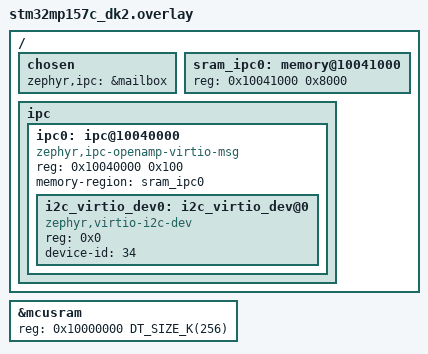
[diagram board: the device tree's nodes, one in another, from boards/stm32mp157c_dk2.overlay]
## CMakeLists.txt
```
cmake_minimum_required(VERSION 3.13.1)
# Copyright (c) 2024  STMicroelectronics
#
# SPDX-License-Identifier: Apache-2.0
#

include($ENV{ZEPHYR_BASE}/cmake/app/boilerplate.cmake NO_POLICY_SCOPE)

project(virtio_i2c_ram)

zephyr_compile_definitions(
  -DMETAL_MAX_DEVICE_REGIONS=2
  -DVIRTIO_SLAVE_ONLY
  )

target_include_directories(app PRIVATE $ENV{ZEPHYR_BASE}/drivers)
target_include_directories(app PRIVATE ${LIBMETAL_INCLUDE_DIR} ${OPENAMP_INCLUDE_DIR} ${PLATFORM_DIR})

target_sources(app PRIVATE src/main_remote.c)

target_include_directories(app PRIVATE ${CMAKE_CURRENT_SOURCE_DIR}/..)
```

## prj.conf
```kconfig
CONFIG_KERNEL_BIN_NAME="zephyr_virtio_i2c_eeprom"
CONFIG_PRINTK=n
CONFIG_IPM=y
CONFIG_PLATFORM_SPECIFIC_INIT=n
CONFIG_MAIN_STACK_SIZE=4096
CONFIG_HEAP_MEM_POOL_SIZE=16384
CONFIG_OPENAMP_MASTER=n
CONFIG_OPENAMP_RSC_TABLE=n
CONFIG_VIRTIO_MSG_SERVICE=y
CONFIG_VIRTIO_MSG_SERVICE_MODE_REMOTE=y
CONFIG_I2C=y
CONFIG_I2C_VIRTIO_DEV=y
CONFIG_I2C_TARGET_BUFFER_MODE=y
CONFIG_RAM_CONSOLE=y
CONFIG_RAM_CONSOLE_BUFFER_SIZE=1024
```

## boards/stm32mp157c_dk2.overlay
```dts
/*
 * Copyright (c) 2024, STMICROELECTRONICS
 *
 * SPDX-License-Identifier: Apache-2.0
 */

/ {
	chosen {
		/*
		 * shared memory reserved for the inter-processor communication
		 */
		zephyr,ipc = &mailbox;
	};


	sram_ipc0: memory@10041000 {
			#memory-region-cells = <0>;
			reg = <0x10041000 0x8000>;
		};

   	ipc {
		#address-cells = <1>;
		#size-cells = <1>;
		ipc0: ipc@10040000  {
			reg = <0x10040000  0x100>;
			compatible = "zephyr,ipc-openamp-virtio-msg";
			memory-region = <&sram_ipc0>;
			status = "okay";

			#address-cells = <1>;
			#size-cells = <0>;
			i2c_virtio_dev0: i2c_virtio_dev@0 {
				compatible = "zephyr,virtio-i2c-dev";
				reg = <0x0>;
                		device-id = <34>;
			};
		};
	};
};

&mcusram {
	reg = <0x10000000 DT_SIZE_K(256)>;
};
```

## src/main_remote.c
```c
// SPDX-License-Identifier: Apache-2.0

/* Copyright (c) 2024, STMicroelectronics */


#include <stdlib.h>
#include <stdio.h>
#include <string.h>

#include <zephyr/device.h>
#include <zephyr/drivers/sensor.h>
#include <zephyr/drivers/i2c.h>
#include <zephyr/drivers/i2c/target/eeprom.h>
#include <zephyr/drivers/ipm.h>
#include <zephyr/ipc/virtio_transport.h>
#include <zephyr/kernel.h>

#include <openamp/open_amp.h>
#include <metal/device.h>

#include <zephyr/logging/log.h>
LOG_MODULE_REGISTER(virtio_i2c_ram, LOG_LEVEL_DBG);

#define I2C_REMOTE_DISP_ADDR 0x3D

/* constant derivated from linker symbols */

#define STACKSIZE (4096)
#define PRIORITY	K_PRIO_PREEMPT(2)


#define RAM_0_ADDR	0x54
#define RAM_1_ADDR	0x56

#define I2C_RAM_SIZE 20
#define I2C_NUM_RAM  2

static K_SEM_DEFINE(data_sem, 0, 1);


struct i2c_ram_t{
	uint8_t i2c_addr;
	uint8_t padding;
	uint8_t offset;
	uint8_t buff[I2C_RAM_SIZE];
};


static struct i2c_ram_t i2c_rams[I2C_NUM_RAM] = {
	{
		.i2c_addr = RAM_0_ADDR,
		.buff = "123456789abcdefghij",
	},
	{
		.i2c_addr = RAM_1_ADDR,
		.buff = "klmnopqrstuvwxyz!:;",
	}
};

struct virtio_i2c_ram_context {
	uint32_t buffer_idx;
	struct virtio_msg_bus_device vmsg_bus;
	const struct virtio_msg_bus_cfg vmsg_bus_cfg;
	struct i2c_target_config config;
	struct i2c_ram_t *ram;
};

static struct virtio_i2c_ram_context ctx[I2C_NUM_RAM];

static int ram_i2c_read(struct i2c_target_config *config, uint8_t **ptr, uint32_t *len)
{
	struct virtio_i2c_ram_context *ctx = CONTAINER_OF(config,
						struct virtio_i2c_ram_context,
						config);
	struct i2c_ram_t *ram =ctx->ram;

	if(I2C_RAM_SIZE < ram->offset)
		return -EINVAL;
	*ptr = &ram->buff[ram->offset];
	*len = I2C_RAM_SIZE - ram->offset ;

	return 0;
}

static void ram_i2c_write(struct i2c_target_config *config, uint8_t *ptr, uint32_t len)
{
	struct virtio_i2c_ram_context *ctx = CONTAINER_OF(config,
						struct virtio_i2c_ram_context,
						config);
	struct i2c_ram_t *ram =ctx->ram;

	/* The first byte is offset */
	ram->offset = *ptr;
	memcpy(&ram->buff[ram->offset], ptr + 1, len - 1);
}

static const struct i2c_target_callbacks i2c_virtio_callbacks = {
	.buf_write_received = ram_i2c_write,
	.buf_read_requested = ram_i2c_read,
};

void virtio_msg_bus(void *u1, void *u2, void *u3)
{
	const struct device *ipc_instance;
	const struct device *virtio_i2c_dev;
	int ret;

	printk("\r\nOpenAMP[remote] virtio msg bus demo started\r\n");

	ipc_instance = DEVICE_DT_GET(DT_NODELABEL(ipc0));
	virtio_i2c_dev = DEVICE_DT_GET(DT_NODELABEL(i2c_virtio_dev0));

	for (int i = 0; i < I2C_NUM_RAM; i++) {
		ctx[i].config.address = i2c_rams[i].i2c_addr;
		ctx[i].config.callbacks = &i2c_virtio_callbacks;
		ctx[i].ram = &i2c_rams[i];
		ret = i2c_target_register(virtio_i2c_dev, &ctx[i].config);
		if (ret) {
			LOG_ERR("Failed to register I2C SLAVE %#x\n", ctx[i].config.address);
			goto task_end;
		}
	}


	ret = ipc_virtio_transport_open_instance(ipc_instance);
	if (ret < 0 && ret != -EALREADY) {
		printk("ipc_service_open_instance() failure\n");
		return;
	}

	while(1);

task_end:
	LOG_DBG("sensor task ended\n");
}

K_THREAD_DEFINE(virtio_trans_thread_id, STACKSIZE, virtio_msg_bus, NULL, NULL, NULL, PRIORITY, 0, 0);
```
